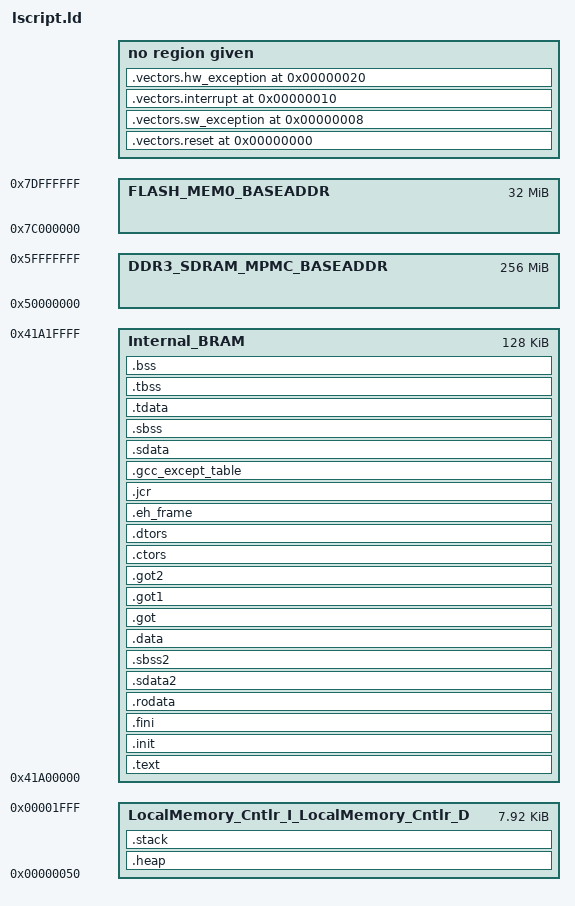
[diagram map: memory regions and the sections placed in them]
/*******************************************************************/
/*                                                                 */
/* This file is automatically generated by linker script generator.*/
/*                                                                 */
/* Version: Xilinx EDK 12.4 EDK_MS4.81d                                */
/*                                                                 */
/* Copyright (c) 2010 Xilinx, Inc.  All rights reserved.           */
/*                                                                 */
/* Description : MicroBlaze Linker Script                          */
/*                                                                 */
/*******************************************************************/

_STACK_SIZE = DEFINED(_STACK_SIZE) ? _STACK_SIZE : 0x1000;
_HEAP_SIZE = DEFINED(_HEAP_SIZE) ? _HEAP_SIZE : 0x400;

/* Define Memories in the system */

MEMORY
{
   LocalMemory_Cntlr_I_LocalMemory_Cntlr_D : ORIGIN = 0x00000050, LENGTH = 0x00001FB0
   Internal_BRAM : ORIGIN = 0x41A00000, LENGTH = 0x00020000
   DDR3_SDRAM_MPMC_BASEADDR : ORIGIN = 0x50000000, LENGTH = 0x10000000
   FLASH_MEM0_BASEADDR : ORIGIN = 0x7C000000, LENGTH = 0x02000000
}

/* Specify the default entry point to the program */

ENTRY(_start)

/* Define the sections, and where they are mapped in memory */

SECTIONS
{
.vectors.reset 0x00000000 : {
   *(.vectors.reset)
} 

.vectors.sw_exception 0x00000008 : {
   *(.vectors.sw_exception)
} 

.vectors.interrupt 0x00000010 : {
   *(.vectors.interrupt)
} 

.vectors.hw_exception 0x00000020 : {
   *(.vectors.hw_exception)
} 

.text : {
   *(.text)
   *(.text.*)
   *(.gnu.linkonce.t.*)
} > Internal_BRAM

.init : {
   KEEP (*(.init))
} > Internal_BRAM

.fini : {
   KEEP (*(.fini))
} > Internal_BRAM

.rodata : {
   __rodata_start = .;
   *(.rodata)
   *(.rodata.*)
   *(.gnu.linkonce.r.*)
   __rodata_end = .;
} > Internal_BRAM

.sdata2 : {
   . = ALIGN(8);
   __sdata2_start = .;
   *(.sdata2)
   *(.sdata2.*)
   *(.gnu.linkonce.s2.*)
   . = ALIGN(8);
   __sdata2_end = .;
} > Internal_BRAM

.sbss2 : {
   __sbss2_start = .;
   *(.sbss2)
   *(.sbss2.*)
   *(.gnu.linkonce.sb2.*)
   __sbss2_end = .;
} > Internal_BRAM

.data : {
   . = ALIGN(4);
   __data_start = .;
   *(.data)
   *(.data.*)
   *(.gnu.linkonce.d.*)
   __data_end = .;
} > Internal_BRAM

.got : {
   *(.got)
} > Internal_BRAM

.got1 : {
   *(.got1)
} > Internal_BRAM

.got2 : {
   *(.got2)
} > Internal_BRAM

.ctors : {
   __CTOR_LIST__ = .;
   ___CTORS_LIST___ = .;
   KEEP (*crtbegin.o(.ctors))
   KEEP (*(EXCLUDE_FILE(*crtend.o) .ctors))
   KEEP (*(SORT(.ctors.*)))
   KEEP (*(.ctors))
   __CTOR_END__ = .;
   ___CTORS_END___ = .;
} > Internal_BRAM

.dtors : {
   __DTOR_LIST__ = .;
   ___DTORS_LIST___ = .;
   KEEP (*crtbegin.o(.dtors))
   KEEP (*(EXCLUDE_FILE(*crtend.o) .dtors))
   KEEP (*(SORT(.dtors.*)))
   KEEP (*(.dtors))
   __DTOR_END__ = .;
   ___DTORS_END___ = .;
} > Internal_BRAM

.eh_frame : {
   *(.eh_frame)
} > Internal_BRAM

.jcr : {
   *(.jcr)
} > Internal_BRAM

.gcc_except_table : {
   *(.gcc_except_table)
} > Internal_BRAM

.sdata : {
   . = ALIGN(8);
   __sdata_start = .;
   *(.sdata)
   *(.sdata.*)
   *(.gnu.linkonce.s.*)
   __sdata_end = .;
} > Internal_BRAM

.sbss : {
   . = ALIGN(4);
   __sbss_start = .;
   *(.sbss)
   *(.sbss.*)
   *(.gnu.linkonce.sb.*)
   . = ALIGN(8);
   __sbss_end = .;
} > Internal_BRAM

.tdata : {
   __tdata_start = .;
   *(.tdata)
   *(.tdata.*)
   *(.gnu.linkonce.td.*)
   __tdata_end = .;
} > Internal_BRAM

.tbss : {
   __tbss_start = .;
   *(.tbss)
   *(.tbss.*)
   *(.gnu.linkonce.tb.*)
   __tbss_end = .;
} > Internal_BRAM

.bss : {
   . = ALIGN(4);
   __bss_start = .;
   *(.bss)
   *(.bss.*)
   *(.gnu.linkonce.b.*)
   *(COMMON)
   . = ALIGN(4);
   __bss_end = .;
} > Internal_BRAM

_SDA_BASE_ = __sdata_start + ((__sbss_end - __sdata_start) / 2 );

_SDA2_BASE_ = __sdata2_start + ((__sbss2_end - __sdata2_start) / 2 );

/* Generate Stack and Heap definitions */

.heap : {
   . = ALIGN(8);
   _heap = .;
   _heap_start = .;
   . += _HEAP_SIZE;
   _heap_end = .;
} > LocalMemory_Cntlr_I_LocalMemory_Cntlr_D

.stack : {
   _stack_end = .;
   . += _STACK_SIZE;
   . = ALIGN(8);
   _stack = .;
   __stack = _stack;
} > LocalMemory_Cntlr_I_LocalMemory_Cntlr_D

_end = .;
}

